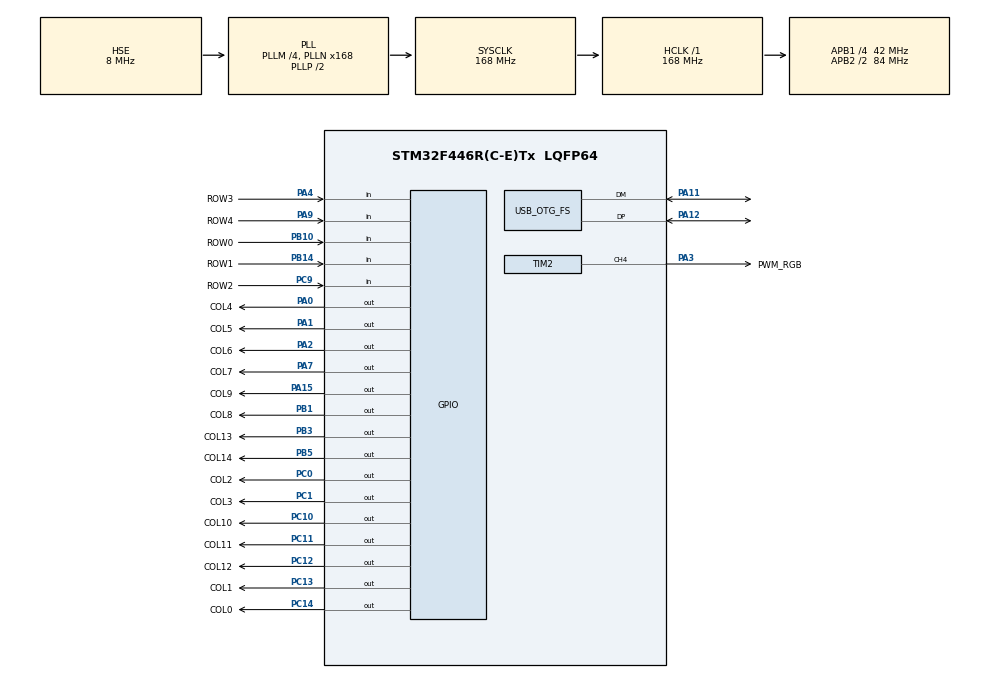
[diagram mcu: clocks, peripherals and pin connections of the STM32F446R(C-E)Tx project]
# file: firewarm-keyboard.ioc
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Dma.Request0=TIM2_CH2/CH4
Dma.TIM2_CH2/CH4.0.Direction=DMA_MEMORY_TO_PERIPH
Dma.TIM2_CH2/CH4.0.FIFOMode=DMA_FIFOMODE_DISABLE
Dma.TIM2_CH2/CH4.0.Instance=DMA1_Stream6
Dma.TIM2_CH2/CH4.0.MemDataAlignment=DMA_MDATAALIGN_WORD
Dma.TIM2_CH2/CH4.0.MemInc=DMA_MINC_ENABLE
Dma.TIM2_CH2/CH4.0.Mode=DMA_NORMAL
Dma.TIM2_CH2/CH4.0.PeriphDataAlignment=DMA_PDATAALIGN_WORD
Dma.TIM2_CH2/CH4.0.PeriphInc=DMA_PINC_DISABLE
Dma.TIM2_CH2/CH4.0.Priority=DMA_PRIORITY_LOW
FREERTOS.INCLUDE_pcTaskGetTaskName=1
FREERTOS.INCLUDE_uxTaskGetStackHighWaterMark2=1
FREERTOS.INCLUDE_vTaskCleanUpResources=1
FREERTOS.INCLUDE_xEventGroupSetBitFromISR=1
FREERTOS.INCLUDE_xSemaphoreGetMutexHolder=1
FREERTOS.INCLUDE_xTaskAbortDelay=1
FREERTOS.INCLUDE_xTaskGetHandle=1
FREERTOS.Tasks01=initTask,24,128,initFunction,As weak,NULL,Dynamic,NULL,NULL
FREERTOS.configENABLE_FPU=1
Mcu.Family=STM32F4
Mcu.Name=STM32F446R(C-E)Tx
Mcu.Package=LQFP64
NVIC.DMA1_Stream6_IRQn=true\:5\:0\:false\:false\:true\:true\:false\:true\:true
NVIC.OTG_FS_IRQn=true\:5\:0\:false\:false\:true\:true\:false\:true\:true
NVIC.PriorityGroup=NVIC_PRIORITYGROUP_4
NVIC.TIM7_IRQn=true\:15\:0\:false\:false\:true\:false\:false\:true\:true
NVIC.TimeBase=TIM7_IRQn
NVIC.TimeBaseIP=TIM7
PA0-WKUP.GPIO_Label=COL4
PA0-WKUP.GPIO_PuPd=GPIO_PULLDOWN
PA0-WKUP.Signal=GPIO_Output
PA1.GPIO_Label=COL5
PA1.GPIO_PuPd=GPIO_PULLDOWN
PA1.Signal=GPIO_Output
PA11.Mode=Device_Only
PA11.Signal=USB_OTG_FS_DM
PA12.GPIO_PuPd=GPIO_PULLUP
PA12.Mode=Device_Only
PA12.Signal=USB_OTG_FS_DP
PA13.Mode=Serial_Wire
PA13.Signal=SYS_JTMS-SWDIO
PA14.Mode=Serial_Wire
PA14.Signal=SYS_JTCK-SWCLK
PA15.GPIO_Label=COL9
PA15.GPIO_PuPd=GPIO_PULLDOWN
PA15.Signal=GPIO_Output
PA2.GPIO_Label=COL6
PA2.GPIO_PuPd=GPIO_PULLDOWN
PA2.Signal=GPIO_Output
PA3.GPIO_Label=PWM_RGB
PA3.GPIO_PuPd=GPIO_PULLDOWN
PA3.GPIO_Speed=GPIO_SPEED_FREQ_VERY_HIGH
PA3.Signal=S_TIM2_CH4
PA4.GPIO_Label=ROW3
PA4.GPIO_PuPd=GPIO_PULLDOWN
PA4.Signal=GPIO_Input
PA7.GPIO_Label=COL7
PA7.GPIO_PuPd=GPIO_PULLDOWN
PA7.Signal=GPIO_Output
PA9.GPIO_Label=ROW4
PA9.GPIO_PuPd=GPIO_PULLDOWN
PA9.Signal=GPIO_Input
PB1.GPIO_Label=COL8
PB1.GPIO_PuPd=GPIO_PULLDOWN
PB1.Signal=GPIO_Output
PB10.GPIO_Label=ROW0
PB10.GPIO_PuPd=GPIO_PULLDOWN
PB10.Signal=GPIO_Input
PB14.GPIO_Label=ROW1
PB14.GPIO_PuPd=GPIO_PULLDOWN
PB14.Signal=GPIO_Input
PB3.GPIO_Label=COL13
PB3.GPIO_PuPd=GPIO_PULLDOWN
PB3.Signal=GPIO_Output
PB5.GPIO_Label=COL14
PB5.GPIO_PuPd=GPIO_PULLDOWN
PB5.Signal=GPIO_Output
PC0.GPIO_Label=COL2
PC0.GPIO_PuPd=GPIO_PULLDOWN
PC0.Signal=GPIO_Output
PC1.GPIO_Label=COL3
PC1.GPIO_PuPd=GPIO_PULLDOWN
PC1.Signal=GPIO_Output
PC10.GPIO_Label=COL10
PC10.GPIO_PuPd=GPIO_PULLDOWN
PC10.Signal=GPIO_Output
PC11.GPIO_Label=COL11
PC11.GPIO_PuPd=GPIO_PULLDOWN
PC11.Signal=GPIO_Output
PC12.GPIO_Label=COL12
PC12.GPIO_PuPd=GPIO_PULLDOWN
PC12.Signal=GPIO_Output
PC13.GPIO_Label=COL1
PC13.GPIO_PuPd=GPIO_PULLDOWN
PC13.Signal=GPIO_Output
PC14-OSC32_IN.GPIO_Label=COL0
PC14-OSC32_IN.GPIO_PuPd=GPIO_PULLDOWN
PC14-OSC32_IN.Signal=GPIO_Output
PC9.GPIO_Label=ROW2
PC9.GPIO_PuPd=GPIO_PULLDOWN
PC9.Signal=GPIO_Input
PH0-OSC_IN.Mode=HSE-External-Oscillator
PH0-OSC_IN.Signal=RCC_OSC_IN
PH1-OSC_OUT.Mode=HSE-External-Oscillator
PH1-OSC_OUT.Signal=RCC_OSC_OUT
ProjectManager.HeapSize=0x200
ProjectManager.StackSize=0x400
ProjectManager.TargetToolchain=CMake
RCC.AHBFreq_Value=168000000
RCC.APB1CLKDivider=RCC_HCLK_DIV4
RCC.APB1Freq_Value=42000000
RCC.APB1TimFreq_Value=84000000
RCC.APB2CLKDivider=RCC_HCLK_DIV2
RCC.APB2Freq_Value=84000000
RCC.APB2TimFreq_Value=168000000
RCC.CortexFreq_Value=168000000
RCC.HCLKFreq_Value=168000000
RCC.HSE_VALUE=8000000
RCC.PLLM=4
RCC.PLLN=168
RCC.PLLQ=7
RCC.SYSCLKFreq_VALUE=168000000
RCC.SYSCLKSource=RCC_SYSCLKSOURCE_PLLCLK
RCC.USBFreq_Value=48000000
RCC.VCOOutputFreq_Value=336000000
SH.S_TIM2_CH4.0=TIM2_CH4,PWM Generation4 CH4
TIM2.Channel-PWM\ Generation4\ CH4=TIM_CHANNEL_4
TIM2.Period=105
USB_DEVICE.CLASS_NAME_FS=HID
USB_DEVICE.PID_HID_FS=22314
USB_DEVICE.VID-HID_FS=2520
USB_DEVICE.VirtualMode-HID_FS=Hid
USB_DEVICE.VirtualModeFS=Hid_FS
USB_OTG_FS.VirtualMode=Device_Only
VP_FREERTOS_VS_CMSIS_V2.Mode=CMSIS_V2
VP_SYS_VS_tim7.Mode=TIM7
VP_TIM2_VS_ClockSourceINT.Mode=Internal
VP_USB_DEVICE_VS_USB_DEVICE_HID_FS.Mode=HID_FS
board=custom

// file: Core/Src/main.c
/* USER CODE BEGIN Header */
/**
  ******************************************************************************
  * @file           : main.c
  * @brief          : Main program body
  ******************************************************************************
  * @attention
  *
  * Copyright (c) 2024 STMicroelectronics.
  * All rights reserved.
  *
  * This software is licensed under terms that can be found in the LICENSE file
  * in the root directory of this software component.
  * If no LICENSE file comes with this software, it is provided AS-IS.
  *
  ******************************************************************************
  */
/* USER CODE END Header */
#include "main.h"
#include "cmsis_os.h"
#include "dma.h"
#include "tim.h"
#include "usb_device.h"
#include "gpio.h"

void SystemClock_Config(void);
void MX_FREERTOS_Init(void);

int main(void)
{

  /* MCU Configuration--------------------------------------------------------*/

  /* Reset of all peripherals, Initializes the Flash interface and the Systick. */
  HAL_Init();

  /* Configure the system clock */
  SystemClock_Config();

  /* Initialize all configured peripherals */
  MX_GPIO_Init();
  MX_DMA_Init();
  MX_TIM2_Init();
  /* USER CODE BEGIN 2 */
//	uint8_t buff[4] = {0, 10, 0 ,0}; // X��������λ����

  /* USER CODE END 2 */

  /* Init scheduler */
  osKernelInitialize();

  /* Call init function for freertos objects (in cmsis_os2.c) */
  MX_FREERTOS_Init();

  /* Start scheduler */
  osKernelStart();

  /* We should never get here as control is now taken by the scheduler */

  /* Infinite loop */
  while (1)
  {

    /* USER CODE BEGIN 3 */
//		extern uint8_t USBD_HID_SendReport(USBD_HandleTypeDef *pdev, uint8_t *report, uint16_t len);
//	  extern USBD_HandleTypeDef hUsbDeviceFS;

//	  USBD_HID_SendReport(&hUsbDeviceFS, buff, 4); // ��������

//	  HAL_Delay(1000); // ����buff�е�ֵ��ÿ������ϵĹ�꽫�����ƶ�һ��

//		ws2812b_show_dot(0,RGB_COLOR);
//	  HAL_Delay(500);
//	  ws2812b_show_dot(1,RGB_COLOR);
//	  HAL_Delay(500);
  }
  /* USER CODE END 3 */
}

void SystemClock_Config(void)
{
  RCC_OscInitTypeDef RCC_OscInitStruct = {0};
  RCC_ClkInitTypeDef RCC_ClkInitStruct = {0};

  /** Configure the main internal regulator output voltage
  */
  __HAL_RCC_PWR_CLK_ENABLE();
  __HAL_PWR_VOLTAGESCALING_CONFIG(PWR_REGULATOR_VOLTAGE_SCALE1);

  /** Initializes the RCC Oscillators according to the specified parameters
  * in the RCC_OscInitTypeDef structure.
  */
  RCC_OscInitStruct.OscillatorType = RCC_OSCILLATORTYPE_HSE;
  RCC_OscInitStruct.HSEState = RCC_HSE_ON;
  RCC_OscInitStruct.PLL.PLLState = RCC_PLL_ON;
  RCC_OscInitStruct.PLL.PLLSource = RCC_PLLSOURCE_HSE;
  RCC_OscInitStruct.PLL.PLLM = 4;
  RCC_OscInitStruct.PLL.PLLN = 168;
  RCC_OscInitStruct.PLL.PLLP = RCC_PLLP_DIV2;
  RCC_OscInitStruct.PLL.PLLQ = 7;
  RCC_OscInitStruct.PLL.PLLR = 2;
  if (HAL_RCC_OscConfig(&RCC_OscInitStruct) != HAL_OK)
  {
    Error_Handler();
  }

  /** Initializes the CPU, AHB and APB buses clocks
  */
  RCC_ClkInitStruct.ClockType = RCC_CLOCKTYPE_HCLK|RCC_CLOCKTYPE_SYSCLK
                              |RCC_CLOCKTYPE_PCLK1|RCC_CLOCKTYPE_PCLK2;
  RCC_ClkInitStruct.SYSCLKSource = RCC_SYSCLKSOURCE_PLLCLK;
  RCC_ClkInitStruct.AHBCLKDivider = RCC_SYSCLK_DIV1;
  RCC_ClkInitStruct.APB1CLKDivider = RCC_HCLK_DIV4;
  RCC_ClkInitStruct.APB2CLKDivider = RCC_HCLK_DIV2;

  if (HAL_RCC_ClockConfig(&RCC_ClkInitStruct, FLASH_LATENCY_5) != HAL_OK)
  {
    Error_Handler();
  }
}

void HAL_TIM_PeriodElapsedCallback(TIM_HandleTypeDef *htim)
{
  if (htim->Instance == TIM7) {
    HAL_IncTick();
  }
}

void Error_Handler(void)
{
  __disable_irq();
  while (1)
  {
  }
}

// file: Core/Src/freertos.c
/* USER CODE BEGIN Header */
/**
  ******************************************************************************
  * File Name          : freertos.c
  * Description        : Code for freertos applications
  ******************************************************************************
  * @attention
  *
  * Copyright (c) 2024 STMicroelectronics.
  * All rights reserved.
  *
  * This software is licensed under terms that can be found in the LICENSE file
  * in the root directory of this software component.
  * If no LICENSE file comes with this software, it is provided AS-IS.
  *
  ******************************************************************************
  */
/* USER CODE END Header */

#include "FreeRTOS.h"
#include "task.h"
#include "main.h"
#include "cmsis_os.h"

/* Definitions for initTask */
osThreadId_t initTaskHandle;
const osThreadAttr_t initTask_attributes = {
  .name = "initTask",
  .stack_size = 128 * 4,
  .priority = (osPriority_t) osPriorityNormal,
};

void initFunction(void *argument);

extern void MX_USB_DEVICE_Init(void);
void MX_FREERTOS_Init(void); /* (MISRA C 2004 rule 8.1) */

void MX_FREERTOS_Init(void) {

  /* Create the thread(s) */
  /* creation of initTask */
  initTaskHandle = osThreadNew(initFunction, NULL, &initTask_attributes);

}

__weak void initFunction(void *argument)
{
  /* init code for USB_DEVICE */
  MX_USB_DEVICE_Init();
  for(;;)
  {
    osDelay(1);
  }
}
